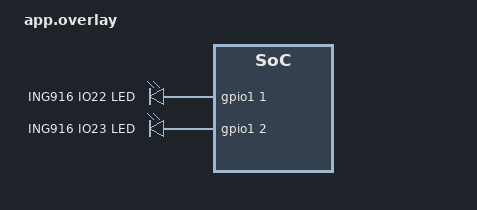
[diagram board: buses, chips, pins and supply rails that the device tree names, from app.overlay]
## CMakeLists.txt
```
# SPDX-License-Identifier: Apache-2.0

cmake_minimum_required(VERSION 3.20.0)
find_package(Zephyr REQUIRED HINTS $ENV{ZEPHYR_BASE})
project(ing916_led_blinky)

target_sources(app PRIVATE src/main.c)
```

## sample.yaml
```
sample:
  name: ING916 dual LED blinky
  description: Blink LEDs connected to ING916 IO22 and IO23 using the Zephyr GPIO API.
common:
  build_only: true
  integration_platforms:
    - ing9168_mini/ing9168
  platform_allow:
    - ing9168_mini/ing9168
  tags:
    - gpio
    - led
tests:
  sample.boards.ingchips.ing916_led_blinky: {}
```

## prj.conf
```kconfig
CONFIG_GPIO=y
CONFIG_PRINTK=y
CONFIG_HEAP_MEM_POOL_SIZE=4096
```

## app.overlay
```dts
/* SPDX-License-Identifier: Apache-2.0 */

#include <zephyr/dt-bindings/gpio/gpio.h>

/ {
	aliases {
		led0 = &led0;
		led1 = &led1;
	};

	leds {
		compatible = "gpio-leds";

		led0: led_0 {
			gpios = <&gpio1 1 GPIO_ACTIVE_HIGH>;
			label = "ING916 IO22 LED";
		};

		led1: led_1 {
			gpios = <&gpio1 2 GPIO_ACTIVE_HIGH>;
			label = "ING916 IO23 LED";
		};
	};
};
```

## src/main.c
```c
/* SPDX-License-Identifier: Apache-2.0 */

#include <zephyr/device.h>
#include <zephyr/drivers/gpio.h>
#include <zephyr/kernel.h>
#include <zephyr/sys/printk.h>

#define BLINK_INTERVAL_MS 500

static const struct gpio_dt_spec leds[] = {
	GPIO_DT_SPEC_GET(DT_ALIAS(led0), gpios),
	GPIO_DT_SPEC_GET(DT_ALIAS(led1), gpios),
};

int main(void)
{
	int ret;

	for (size_t i = 0; i < ARRAY_SIZE(leds); i++) {
		if (!gpio_is_ready_dt(&leds[i])) {
			printk("LED%u GPIO controller is not ready\n", (unsigned int)i);
			return 0;
		}

		ret = gpio_pin_configure_dt(&leds[i], GPIO_OUTPUT_INACTIVE);
		if (ret < 0) {
			printk("Failed to configure LED%u: %d\n", (unsigned int)i, ret);
			return 0;
		}
	}

	printk("Blinking ING916 board LEDs (IO22 and IO23)\n");

	while (true) {
		for (size_t i = 0; i < ARRAY_SIZE(leds); i++) {
			ret = gpio_pin_toggle_dt(&leds[i]);
			if (ret < 0) {
				printk("Failed to toggle LED%u: %d\n", (unsigned int)i, ret);
				return 0;
			}
		}

		k_msleep(BLINK_INTERVAL_MS);
	}

	return 0;
}
```
